AUTOSAR XML (schema 4-2-2)
package /ComSWC
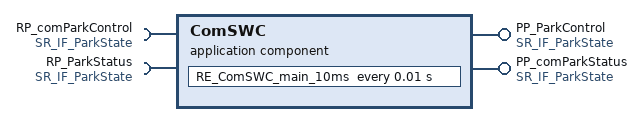
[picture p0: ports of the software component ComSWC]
  application sw component type ComSWC
    provide port PP_ParkControl: provided-interface=SR_IF_ParkState
    provide port PP_comParkStatus: provided-interface=SR_IF_ParkState
    require port RP_comParkControl: required-interface=SR_IF_ParkState
    require port RP_ParkStatus: required-interface=SR_IF_ParkState
    behavior SwcInternalBehavior: data-type-mapping=DataTypeMappingSet
      timing event TE_RE_ComSWC_main_10ms: start-on-event=RE_ComSWC_main_10ms, period=0.01
      runnable RE_ComSWC_main_10ms
        data-receive-point-by-arguments:
          access DRPA_DE_ParkState_0: accessed-variable=RP_ParkStatus.DE_ParkState
          access DRPA_DE_ParkState_1: accessed-variable=RP_comParkControl.DE_ParkState
        data-send-points:
          access DSP_DE_ParkState_0: accessed-variable=PP_comParkStatus.DE_ParkState
          access DSP_DE_ParkState_1: accessed-variable=PP_ParkControl.DE_ParkState
